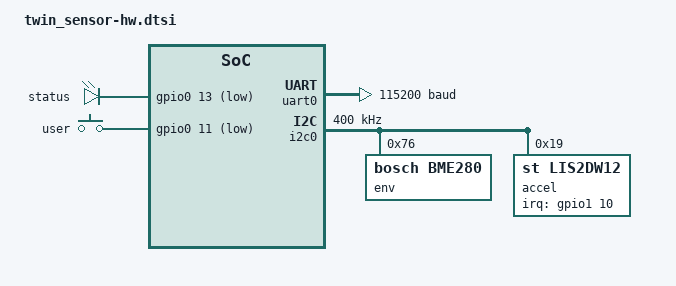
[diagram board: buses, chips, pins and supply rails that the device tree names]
/* GENERATED by scripts/hwsync.py from hardware.yaml. Do not edit; run `west hwsync generate`. */

#include <zephyr/dt-bindings/input/input-event-codes.h>

/ {
	chosen {
		zephyr,console = &uart0;
		zephyr,shell-uart = &uart0;
		zephyr,uart-mcumgr = &uart0;
	};

	leds {
		compatible = "gpio-leds";
		led_status: led_status {
			gpios = <&gpio0 13 GPIO_ACTIVE_LOW>;
			label = "status";
		};
	};

	buttons {
		compatible = "gpio-keys";
		button_user: button_user {
			gpios = <&gpio0 11 (GPIO_PULL_UP | GPIO_ACTIVE_LOW)>;
			label = "user";
			zephyr,code = <INPUT_KEY_0>;
		};
	};

	aliases {
		led0 = &led_status;
		sw0 = &button_user;
		env = &env;
		accel = &accel;
	};
};

&gpio0 {
	status = "okay";
};

&gpio1 {
	status = "okay";
};

&gpiote {
	status = "okay";
};

&uart0 {
	status = "okay";
	current-speed = <115200>;
	pinctrl-0 = <&uart0_default>;
	pinctrl-1 = <&uart0_sleep>;
	pinctrl-names = "default", "sleep";
};

&i2c0 {
	compatible = "nordic,nrf-twi";
	status = "okay";
	clock-frequency = <I2C_BITRATE_FAST>;
	pinctrl-0 = <&i2c0_default>;
	pinctrl-1 = <&i2c0_sleep>;
	pinctrl-names = "default", "sleep";

	env: bme280@76 {
		compatible = "bosch,bme280";
		reg = <0x76>;
	};

	accel: lis2dw12@19 {
		compatible = "st,lis2dw12";
		reg = <0x19>;
		irq-gpios = <&gpio1 10 GPIO_ACTIVE_HIGH>;
	};
};
